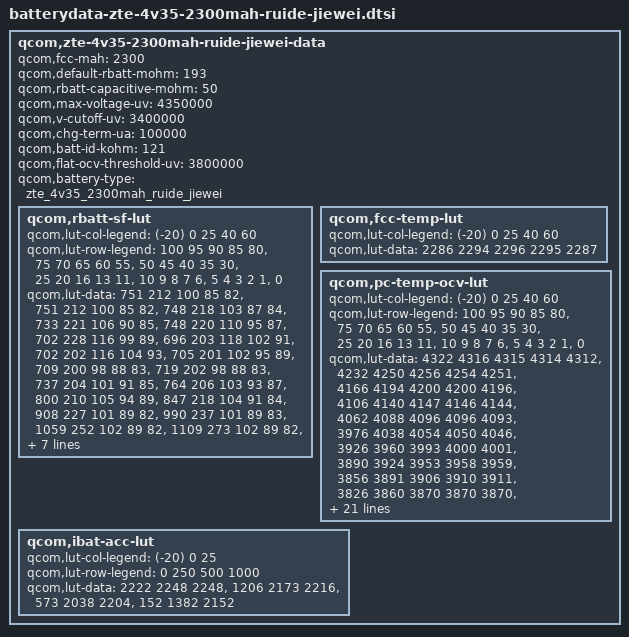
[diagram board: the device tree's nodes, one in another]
/* Copyright (c) 2014, The Linux Foundation. All rights reserved.
 *
 * This program is free software; you can redistribute it and/or modify
 * it under the terms of the GNU General Public License version 2 and
 * only version 2 as published by the Free Software Foundation.
 *
 * This program is distributed in the hope that it will be useful,
 * but WITHOUT ANY WARRANTY; without even the implied warranty of
 * MERCHANTABILITY or FITNESS FOR A PARTICULAR PURPOSE.  See the
 * GNU General Public License for more details.
 */
 qcom,zte-4v35-2300mah-ruide-jiewei-data {
	qcom,fcc-mah = <2300>;
	qcom,default-rbatt-mohm = <193>;
	qcom,rbatt-capacitive-mohm = <50>;
	qcom,max-voltage-uv = <4350000>;
	qcom,v-cutoff-uv = <3400000>;
	qcom,chg-term-ua = <100000>;
	qcom,batt-id-kohm = <121>;
	qcom,flat-ocv-threshold-uv = <3800000>;
	qcom,battery-type = "zte_4v35_2300mah_ruide_jiewei";

	qcom,rbatt-sf-lut {
		qcom,lut-col-legend = <(-20) 0 25 40 60>;
		qcom,lut-row-legend = <100 95 90 85 80>,
				<75 70 65 60 55>,
				<50 45 40 35 30>,
				<25 20 16 13 11>,
				<10 9 8 7 6>,
				<5 4 3 2 1>,
				<0>;
		qcom,lut-data = <751 212 100 85 82>,
				<751 212 100 85 82>,
				<748 218 103 87 84>,
				<733 221 106 90 85>,
				<748 220 110 95 87>,
				<702 228 116 99 89>,
				<696 203 118 102 91>,
				<702 202 116 104 93>,
				<705 201 102 95 89>,
				<709 200 98 88 83>,
				<719 202 98 88 83>,
				<737 204 101 91 85>,
				<764 206 103 93 87>,
				<800 210 105 94 89>,
				<847 218 104 91 84>,
				<908 227 101 89 82>,
				<990 237 101 89 83>,
				<1059 252 102 89 82>,
				<1109 273 102 89 82>,
				<1116 287 102 89 83>,
				<1116 296 105 90 84>,
				<1124 306 106 92 84>,
				<1130 317 108 93 84>,
				<1192 330 110 94 84>,
				<1296 342 109 91 83>,
				<1461 354 107 91 83>,
				<1704 376 110 92 84>,
				<2058 406 113 94 86>,
				<2694 448 120 98 91>,
				<6267 537 140 118 112>,
				<94483 40839 31304 16453 24902>;
	};

	qcom,fcc-temp-lut {
		qcom,lut-col-legend = <(-20) 0 25 40 60>;
		qcom,lut-data = <2286 2294 2296 2295 2287>;
	};

	qcom,pc-temp-ocv-lut {
		qcom,lut-col-legend = <(-20) 0 25 40 60>;
		qcom,lut-row-legend = <100 95 90 85 80>,
				<75 70 65 60 55>,
				<50 45 40 35 30>,
				<25 20 16 13 11>,
				<10 9 8 7 6>,
				<5 4 3 2 1>,
				<0>;
		qcom,lut-data = <4322 4316 4315 4314 4312>,
				<4232 4250 4256 4254 4251>,
				<4166 4194 4200 4200 4196>,
				<4106 4140 4147 4146 4144>,
				<4062 4088 4096 4096 4093>,
				<3976 4038 4054 4050 4046>,
				<3926 3960 3993 4000 4001>,
				<3890 3924 3953 3958 3959>,
				<3856 3891 3906 3910 3911>,
				<3826 3860 3870 3870 3870>,
				<3802 3833 3842 3842 3842>,
				<3785 3810 3819 3820 3820>,
				<3771 3791 3800 3801 3800>,
				<3759 3776 3784 3784 3784>,
				<3747 3764 3768 3764 3756>,
				<3734 3752 3752 3743 3731>,
				<3720 3734 3732 3724 3710>,
				<3702 3716 3712 3702 3689>,
				<3685 3706 3694 3686 3673>,
				<3670 3699 3688 3680 3669>,
				<3661 3695 3687 3680 3668>,
				<3650 3691 3686 3678 3666>,
				<3637 3686 3682 3676 3662>,
				<3620 3678 3678 3669 3654>,
				<3600 3660 3661 3649 3632>,
				<3570 3628 3626 3612 3595>,
				<3532 3582 3579 3564 3546>,
				<3480 3522 3518 3502 3486>,
				<3398 3437 3436 3420 3403>,
				<3260 3300 3312 3294 3274>,
				<3000 3000 3000 3012 3000>;
	};
		qcom,ibat-acc-lut {
		qcom,lut-col-legend = <(-20) 0 25>;
		qcom,lut-row-legend = <0 250 500 1000>;
		qcom,lut-data = <2222 2248 2248>,
				<1206 2173 2216>,
				<573 2038 2204>,
				<152 1382 2152>;
	};

};
